# ES32F0xx register map
File version: 1.0
Registers are 32-bit, read-write, reset 0x0 unless marked. A register's access mark holds for its fields unless they carry their own. Offsets are from the block's base; [hi:lo] are bit positions; {n}, {i} and the like mark numbered series; 'fields as' and 'values as' point back to an identical list.

## RMU — Reset Manage Unit
Base 0x40080800
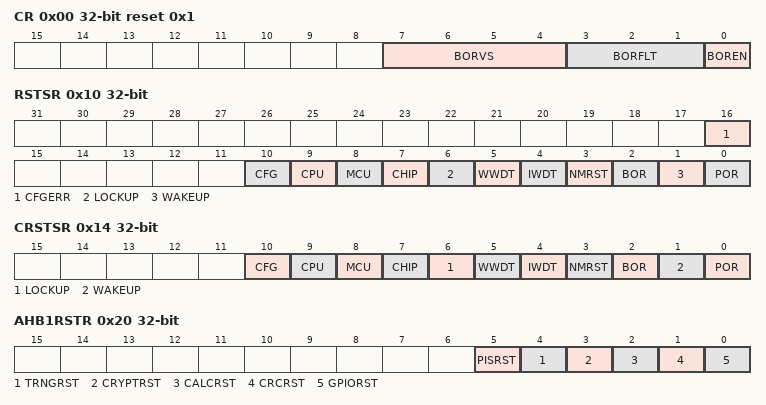
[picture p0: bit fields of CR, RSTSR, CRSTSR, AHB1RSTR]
0x00 CR reset 0x1
  [7:4] BORVS, [3:1] BORFLT, [0] BOREN
0x10 RSTSR read
  [16] CFGERR, [10] CFG, [9] CPU, [8] MCU, [7] CHIP, [6] LOCKUP, [5] WWDT, [4] IWDT, [3] NMRST, [2] BOR, [1] WAKEUP, [0] POR
0x14 CRSTSR write
  [10] CFG, [9] CPU, [8] MCU, [7] CHIP, [6] LOCKUP, [5] WWDT, [4] IWDT, [3] NMRST, [2] BOR, [1] WAKEUP, [0] POR
0x20 AHB1RSTR write
  [5] PISRST, [4] TRNGRST, [3] CRYPTRST, [2] CALCRST, [1] CRCRST, [0] GPIORST
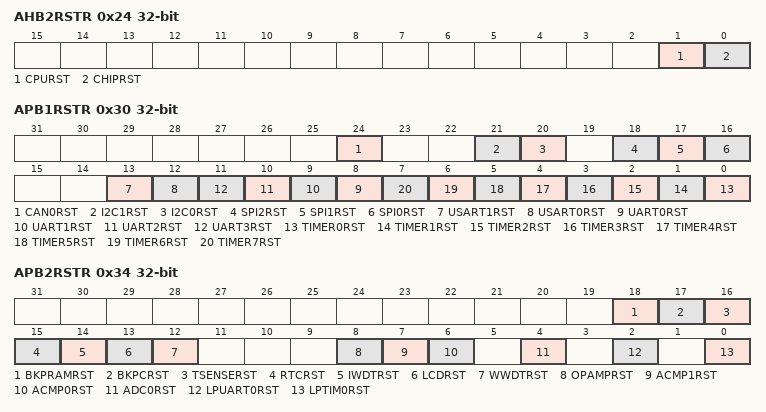
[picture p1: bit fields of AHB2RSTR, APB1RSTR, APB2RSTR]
0x24 AHB2RSTR write
  [1] CPURST, [0] CHIPRST
0x30 APB1RSTR write
  [24] CAN0RST, [21] I2C1RST, [20] I2C0RST, [18] SPI2RST, [17] SPI1RST, [16] SPI0RST, [13] USART1RST, [12] USART0RST, [n+8] UART{n}RST (n=0..3), [n] TIMER{n}RST (n=0..7)
0x34 APB2RSTR write
  [18] BKPRAMRST, [17] BKPCRST, [16] TSENSERST, [15] RTCRST, [14] IWDTRST, [13] LCDRST, [12] WWDTRST, [8] OPAMPRST, [7] ACMP1RST, [6] ACMP0RST, [4] ADC0RST, [2] LPUART0RST, [0] LPTIM0RST

## PMU — Pow Manage Unit
Base 0x40080C00
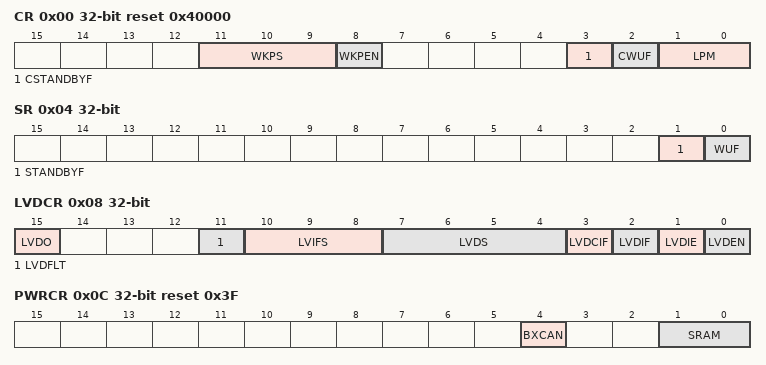
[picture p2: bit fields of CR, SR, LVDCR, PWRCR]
0x00 CR reset 0x40000
  [11:9] WKPS, [8] WKPEN, [3] CSTANDBYF, [2] CWUF, [1:0] LPM
0x04 SR read
  [1] STANDBYF, [0] WUF
0x08 LVDCR
  [15] LVDO, [11] LVDFLT, [10:8] LVIFS, [7:4] LVDS, [3] LVDCIF, [2] LVDIF, [1] LVDIE, [0] LVDEN
0x0C PWRCR reset 0x3F
  [4] BXCAN, [1:0] SRAM
0x10 TWUR reset 0xFFF
  [11:0] TWU
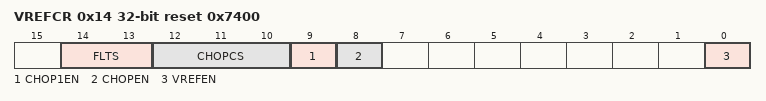
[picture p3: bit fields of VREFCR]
0x14 VREFCR reset 0x7400
  [14:13] FLTS, [12:10] CHOPCS, [9] CHOP1EN, [8] CHOPEN, [0] VREFEN

## MSC — MSC Unit
Base 0x40081000
0x00 FLASHKEY read reset 0x3
  [1:0] STATUS
0x04 INFOKEY read reset 0x3
  [1:0] STATUS
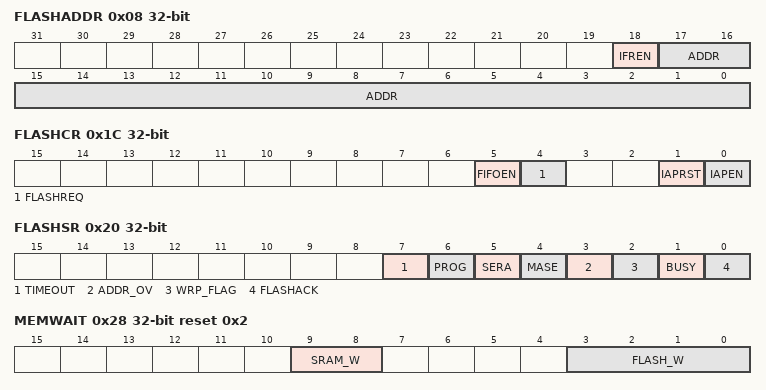
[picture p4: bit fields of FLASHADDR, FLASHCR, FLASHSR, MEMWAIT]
0x08 FLASHADDR
  [18] IFREN, [17:0] ADDR
0x0C FLASHFIFO write
  [31:0] FIFO
0x10 FLASHDL
  [31:0] DATAL
0x14 FLASHDH
  [31:0] DATAH
0x18 FLASHCMD write
  [31:0] CMD
0x1C FLASHCR
  [5] FIFOEN, [4] FLASHREQ, [1] IAPRST, [0] IAPEN
0x20 FLASHSR read
  [7] TIMEOUT, [6] PROG, [5] SERA, [4] MASE, [3] ADDR_OV, [2] WRP_FLAG, [1] BUSY, [0] FLASHACK
0x24 FLASHPL
  [15:0] PROG_LEN
0x28 MEMWAIT reset 0x2
  [9:8] SRAM_W, [3:0] FLASH_W

## DMA — Direct Memory Access
Base 0x4000C000
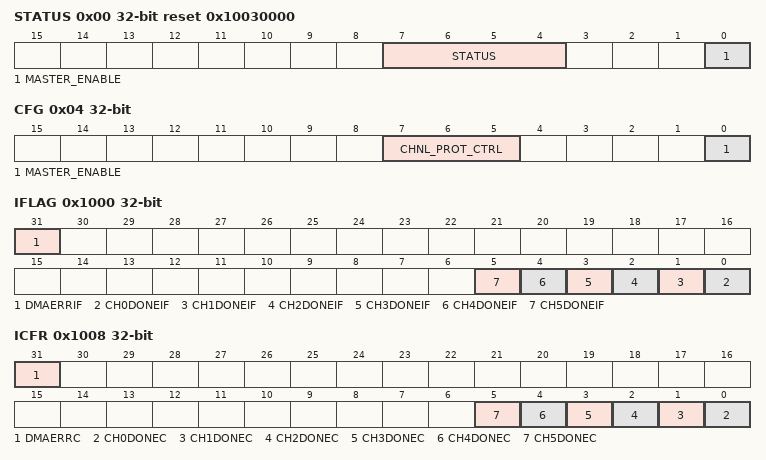
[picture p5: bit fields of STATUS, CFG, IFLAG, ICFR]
0x00 STATUS read reset 0x10030000
  [7:4] STATUS, [0] MASTER_ENABLE
0x04 CFG
  [7:5] CHNL_PROT_CTRL, [0] MASTER_ENABLE
0x08 CTRLBASE
  [31:9] CTRL_BASE_PTR
0x0C ALTCTRLBASE read
  [31:0] ALT_CTRL_BASE_PTR
0x10 CHWAITSTATUS read
  [31:0] DMA_WAITONREQ_STATUS
0x14 CHSWREQ read
0x18 CHUSEBURSTSET
  [31:0] CHNL_USEBURST_SET
0x1C CHUSEBURSTCLR write
  [31:0] CHNL_USEBURST_CLR
0x20 CHREQMASKSET
  [31:0] CHNL_REQ_MASK_SET
0x24 CHREQMASKCLR write
  [31:0] CHNL_REQ_MASK_CLR
0x28 CHENSET
  [31:0] CHNL_ENABLE_SET
0x2C CHENCLR write
  [31:0] CHNL_ENABLE_CLR
0x30 CHPRIALTSET
  [31:0] CHNL_PRI_ALT_SET
0x34 CHPRIALTCLR write
  [31:0] CHNL_PRI_ALT_CLR
0x38 CHPRSET
  [31:0] CHNL_PRIORITY_SET
0x3C CHPRCLR write
  [31:0] CHNL_PRIORITY_CLR
0x4C ERRCLR
  [0] ERR_CLR
0x1000 IFLAG read
  [31] DMAERRIF, [n] CH{n}DONEIF (n=0..5)
0x1008 ICFR write
  [31] DMAERRC, [n] CH{n}DONEC (n=0..5)
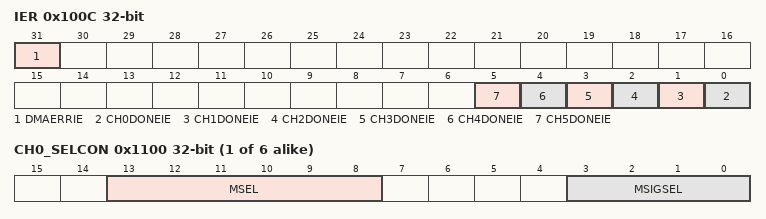
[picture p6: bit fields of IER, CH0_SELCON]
0x100C IER
  [31] DMAERRIE, [n] CH{n}DONEIE (n=0..5)
{0x1100+4i} CH{i}_SELCON (i=0..5)
  [13:8] MSEL, [3:0] MSIGSEL

## PIS — Peripheral Connect
Base 0x40086000
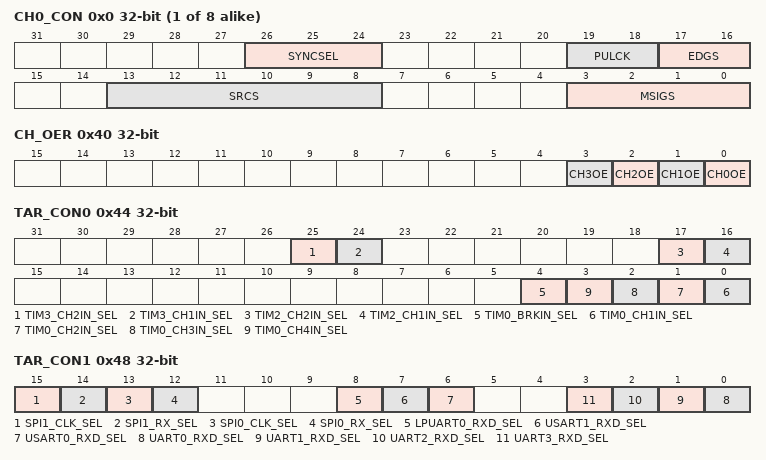
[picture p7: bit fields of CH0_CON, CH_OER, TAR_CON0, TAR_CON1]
{0x0+4i} CH{i}_CON (i=0..7)
  [26:24] SYNCSEL, [19:18] PULCK, [17:16] EDGS, [13:8] SRCS, [3:0] MSIGS
0x40 CH_OER
  [n] CH{n}OE (n=0..3)
0x44 TAR_CON0
  [25] TIM3_CH2IN_SEL, [24] TIM3_CH1IN_SEL, [17] TIM2_CH2IN_SEL, [16] TIM2_CH1IN_SEL, [4] TIM0_BRKIN_SEL, [n-1] TIM0_CH{n}IN_SEL (n=1..4)
0x48 TAR_CON1
  [15] SPI1_CLK_SEL, [14] SPI1_RX_SEL, [13] SPI0_CLK_SEL, [12] SPI0_RX_SEL, [8] LPUART0_RXD_SEL, [7] USART1_RXD_SEL, [6] USART0_RXD_SEL, [n] UART{n}_RXD_SEL (n=0..3)
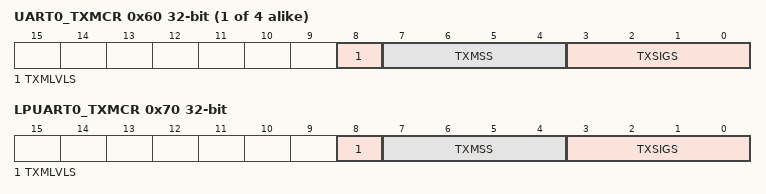
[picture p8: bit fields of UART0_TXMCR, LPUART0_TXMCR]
{0x60+4i} UART{i}_TXMCR (i=0..3)
  [8] TXMLVLS, [7:4] TXMSS, [3:0] TXSIGS
0x70 LPUART0_TXMCR
  [8] TXMLVLS, [7:4] TXMSS, [3:0] TXSIGS

## RTC — Real Time Clock
Base 0x40048400
0x00 WPR read reset 0x1
  [0] WP
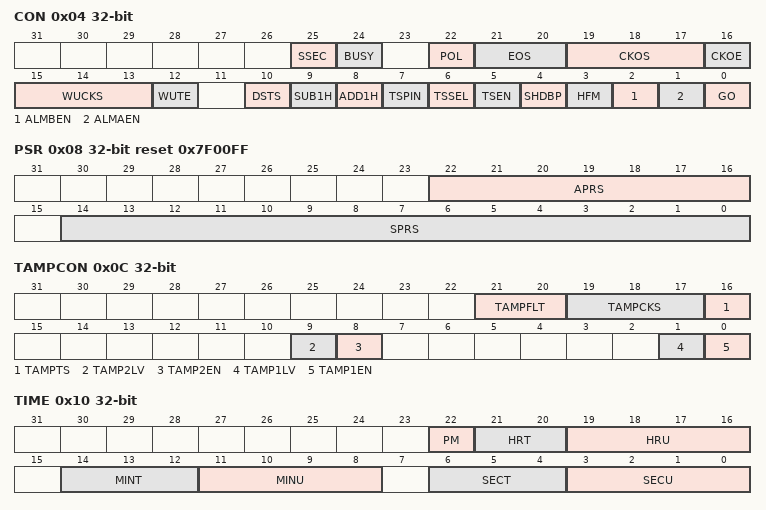
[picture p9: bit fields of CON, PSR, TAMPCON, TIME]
0x04 CON
  [25] SSEC, [24] BUSY, [22] POL, [21:20] EOS, [19:17] CKOS, [16] CKOE, [15:13] WUCKS, [12] WUTE, [10] DSTS, [9] SUB1H, [8] ADD1H, [7] TSPIN, [6] TSSEL, [5] TSEN, [4] SHDBP, [3] HFM, [2] ALMBEN, [1] ALMAEN, [0] GO
0x08 PSR reset 0x7F00FF
  [22:16] APRS, [14:0] SPRS
0x0C TAMPCON
  [21:20] TAMPFLT, [19:17] TAMPCKS, [16] TAMPTS, [9] TAMP2LV, [8] TAMP2EN, [1] TAMP1LV, [0] TAMP1EN
0x10 TIME
  [22] PM, [21:20] HRT, [19:16] HRU, [14:12] MINT, [11:8] MINU, [6:4] SECT, [3:0] SECU
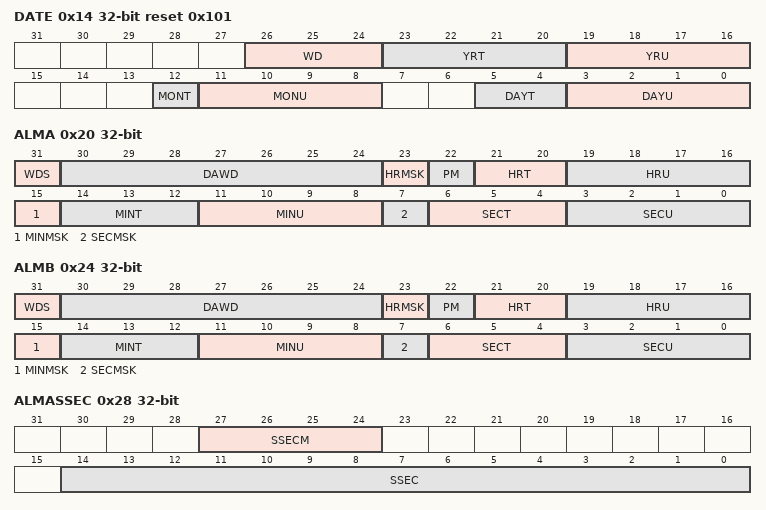
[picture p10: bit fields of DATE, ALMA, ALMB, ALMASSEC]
0x14 DATE reset 0x101
  [26:24] WD, [23:20] YRT, [19:16] YRU, [12] MONT, [11:8] MONU, [5:4] DAYT, [3:0] DAYU
0x18 SSEC read
  [15:0] VAL
0x1C WUMAT reset 0xFFFF
  [15:0] VAL
0x20 ALMA
  [31] WDS, [30:24] DAWD, [23] HRMSK, [22] PM, [21:20] HRT, [19:16] HRU, [15] MINMSK, [14:12] MINT, [11:8] MINU, [7] SECMSK, [6:4] SECT, [3:0] SECU
0x24 ALMB
  fields as ALMA
0x28 ALMASSEC
  [27:24] SSECM, [14:0] SSEC
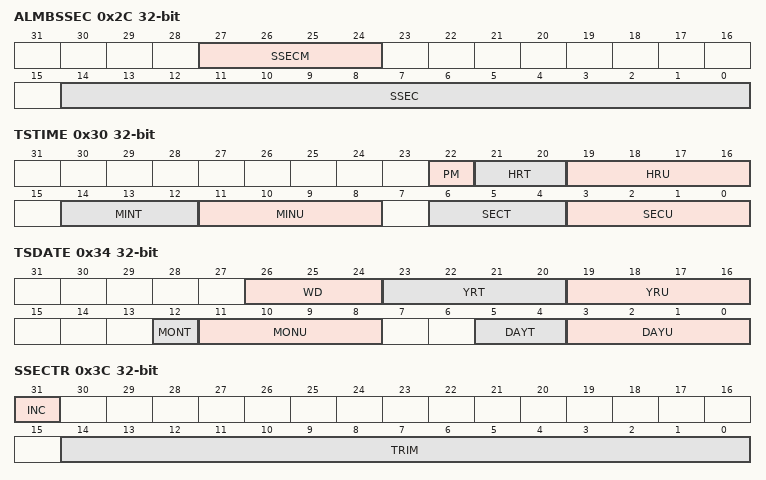
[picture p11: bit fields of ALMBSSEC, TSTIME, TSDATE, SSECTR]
0x2C ALMBSSEC
  [27:24] SSECM, [14:0] SSEC
0x30 TSTIME read
  fields as TIME
0x34 TSDATE read
  fields as DATE
0x38 TSSSEC read
  [15:0] SSEC
0x3C SSECTR write
  [31] INC, [14:0] TRIM
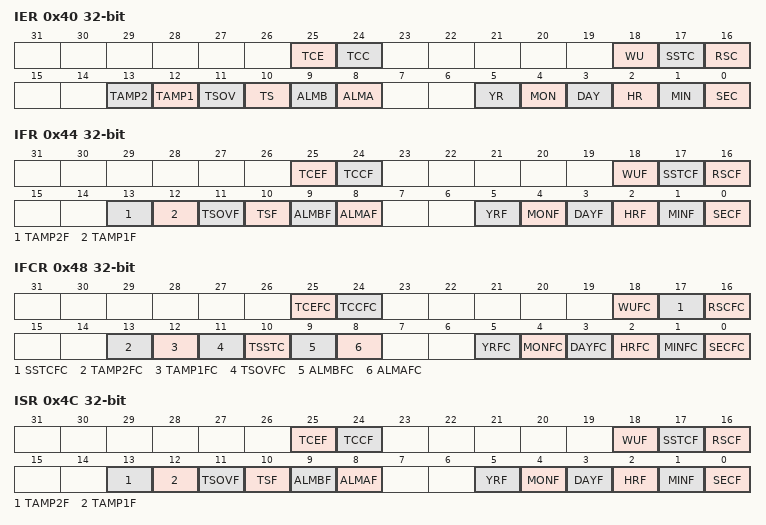
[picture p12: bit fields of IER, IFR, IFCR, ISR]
0x40 IER
  [25] TCE, [24] TCC, [18] WU, [17] SSTC, [16] RSC, [13] TAMP2, [12] TAMP1, [11] TSOV, [10] TS, [9] ALMB, [8] ALMA, [5] YR, [4] MON, [3] DAY, [2] HR, [1] MIN, [0] SEC
0x44 IFR read
  [25] TCEF, [24] TCCF, [18] WUF, [17] SSTCF, [16] RSCF, [13] TAMP2F, [12] TAMP1F, [11] TSOVF, [10] TSF, [9] ALMBF, [8] ALMAF, [5] YRF, [4] MONF, [3] DAYF, [2] HRF, [1] MINF, [0] SECF
0x48 IFCR write
  [25] TCEFC, [24] TCCFC, [18] WUFC, [17] SSTCFC, [16] RSCFC, [13] TAMP2FC, [12] TAMP1FC, [11] TSOVFC, [10] TSSTC, [9] ALMBFC, [8] ALMAFC, [5] YRFC, [4] MONFC, [3] DAYFC, [2] HRFC, [1] MINFC, [0] SECFC
0x4C ISR read
  fields as IFR
0x50 CALWPR read reset 0x1
  [0] WP
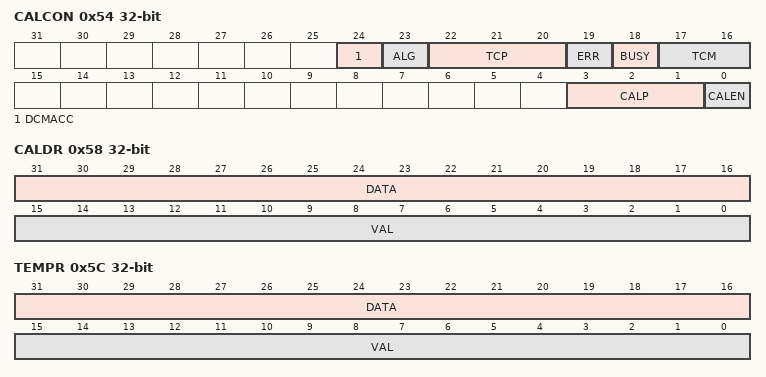
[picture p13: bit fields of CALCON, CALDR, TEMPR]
0x54 CALCON
  [24] DCMACC, [23] ALG, [22:20] TCP, [19] ERR, [18] BUSY, [17:16] TCM, [3:1] CALP, [0] CALEN
0x58 CALDR
  [31:16] DATA, [15:0] VAL
0x5C TEMPR
  [31:16] DATA, [15:0] VAL
0x88 TEMPBDR
  [15:0] VAL
0x100 BKP
